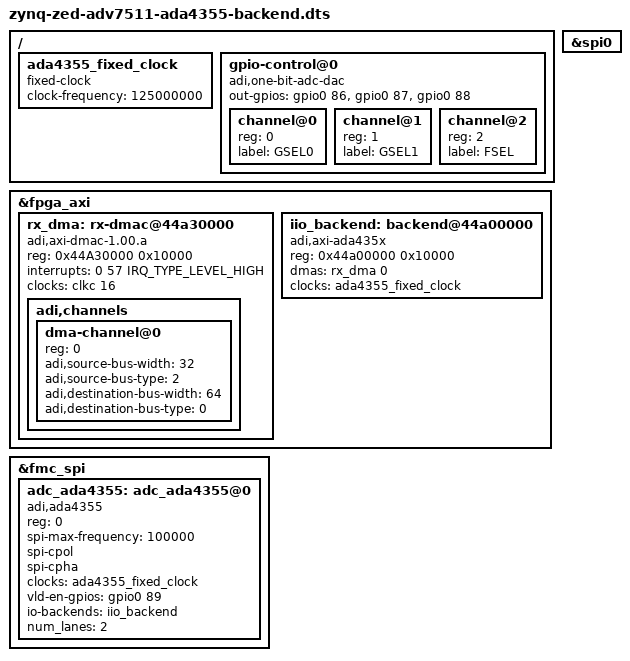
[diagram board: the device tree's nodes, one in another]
// SPDX-License-Identifier: GPL-2.0
/*
 * Analog Devices ada4355
 *
 * hdl_project: <ada4355_fmc/zed>
 * board_revision: <>
 *
 * Copyright (C) 2026 Analog Devices Inc.
 */
/dts-v1/;

#include <dt-bindings/gpio/gpio.h>

#include "zynq-zed.dtsi"
#include "zynq-zed-adv7511.dtsi"

/ {
	ada4355_fixed_clock: ada4355_fixed_clock{
		compatible = "fixed-clock";
		#clock-cells = <0>;
		clock-frequency = <125000000>;
	};

	gpio-control@0 {
		compatible = "adi,one-bit-adc-dac";
		#address-cells = <1>;
		#size-cells = <0>;
		out-gpios = <&gpio0 86 GPIO_ACTIVE_HIGH>,
			    <&gpio0 87 GPIO_ACTIVE_HIGH>,
			    <&gpio0 88 GPIO_ACTIVE_HIGH>;

		channel@0 {
			reg = <0>;
			label = "GSEL0";
		};
		channel@1 {
			reg = <1>;
			label = "GSEL1";
		};
		channel@2 {
			reg = <2>;
			label = "FSEL";
		};
	};
};

&fpga_axi {
	rx_dma: rx-dmac@44a30000 {
		compatible = "adi,axi-dmac-1.00.a";
		reg = <0x44A30000 0x10000>;
		#dma-cells = <1>;
		interrupts = <0 57 IRQ_TYPE_LEVEL_HIGH>;
		clocks = <&clkc 16>;

		adi,channels {
			#size-cells = <0>;
			#address-cells = <1>;

			dma-channel@0 {
				reg = <0>;
				adi,source-bus-width = <32>;
				adi,source-bus-type = <2>;
				adi,destination-bus-width = <64>;
				adi,destination-bus-type = <0>;
			};
		};
	};

	iio_backend: backend@44a00000{
		compatible = "adi,axi-ada435x";
		reg = <0x44a00000 0x10000>;
		dmas = <&rx_dma 0>;
		dma-names = "rx";
		clocks = <&ada4355_fixed_clock>;
	};

};

&spi0 {
	status = "okay";
};

#define fmc_spi spi0

&fmc_spi {

	adc_ada4355: adc_ada4355@0 {
		compatible = "adi,ada4355";
		reg = <0>;
		spi-max-frequency = <100000>;
		spi-cpol;
		spi-cpha;
		clocks = <&ada4355_fixed_clock>;
		clock-names = "adc_clk";
		vld-en-gpios = <&gpio0 89 GPIO_ACTIVE_HIGH>;
		io-backends = <&iio_backend>;
		num_lanes = <2>;
	};
};
